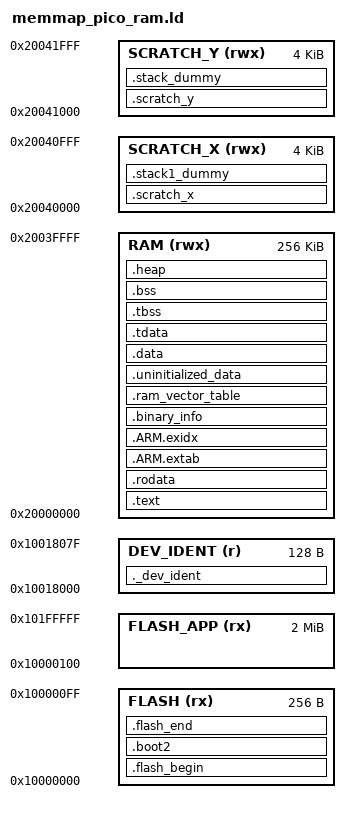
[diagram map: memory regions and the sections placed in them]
/* RAM-only linker script for RP2040 Pico Frankly Bootloader
   Boot2 stage is in flash (required), entire bootloader runs from RAM
   This eliminates all XIP conflicts during flash operations
*/

MEMORY
{
    /* Boot2 stage MUST be in flash - this is hardcoded in RP2040 ROM */
    FLASH(rx) : ORIGIN = 0x10000000, LENGTH = 256
    /* Reserve rest of flash for applications */
    FLASH_APP(rx) : ORIGIN = 0x10000100, LENGTH = 2048k - 256
    /* Entire bootloader runs from RAM */
    RAM(rwx) : ORIGIN = 0x20000000, LENGTH = 256k
    SCRATCH_X(rwx) : ORIGIN = 0x20040000, LENGTH = 4k
    SCRATCH_Y(rwx) : ORIGIN = 0x20041000, LENGTH = 4k
    /* Device identification section in flash for bootflash tool */
    DEV_IDENT(r) : ORIGIN = 0x10018000, LENGTH = 128
}

ENTRY(_entry_point)

SECTIONS
{
    .flash_begin : {
        __flash_binary_start = .;
    } > FLASH

    /* Boot2 stage MUST be in flash - RP2040 ROM requirement */
    .boot2 : {
        __boot2_start__ = .;
        KEEP (*(.boot2))
        __boot2_end__ = .;
    } > FLASH

    .flash_end : {
        PROVIDE(__flash_binary_end = .);
    } > FLASH

    ASSERT(__boot2_end__ - __boot2_start__ == 256,
        "ERROR: Pico second stage bootloader must be 256 bytes in size")

    /* Device identification section for bootflash tool */
    ._dev_ident :
    {
        . = ALIGN(4);
        KEEP(*(._dev_ident))
        . = ALIGN(4);
    } > DEV_IDENT

    /* Everything else runs from RAM - eliminates XIP conflicts */
    .text : {
        __logical_binary_start = .;
        __ram_start__ = .;

        /* Vector table and reset code */
        KEEP (*(.vectors))
        KEEP (*(.binary_info_header))
        __binary_info_header_end = .;
        KEEP (*(.embedded_block))
        __embedded_block_end = .;
        KEEP (*(.reset))

        /* All code in RAM */
        *(.init)
        *(.text*)
        *(.fini)

        /* C++ constructors/destructors */
        *crtbegin.o(.ctors)
        *crtbegin?.o(.ctors)
        *(EXCLUDE_FILE(*crtend?.o *crtend.o) .ctors)
        *(SORT(.ctors.*))
        *(.ctors)
        *crtbegin.o(.dtors)
        *crtbegin?.o(.dtors)
        *(EXCLUDE_FILE(*crtend?.o *crtend.o) .dtors)
        *(SORT(.dtors.*))
        *(.dtors)

        . = ALIGN(4);
        /* preinit data */
        PROVIDE_HIDDEN (__preinit_array_start = .);
        KEEP(*(SORT(.preinit_array.*)))
        KEEP(*(.preinit_array))
        PROVIDE_HIDDEN (__preinit_array_end = .);

        . = ALIGN(4);
        /* init data */
        PROVIDE_HIDDEN (__init_array_start = .);
        KEEP(*(SORT(.init_array.*)))
        KEEP(*(.init_array))
        PROVIDE_HIDDEN (__init_array_end = .);

        . = ALIGN(4);
        /* finit data */
        PROVIDE_HIDDEN (__fini_array_start = .);
        *(SORT(.fini_array.*))
        *(.fini_array)
        PROVIDE_HIDDEN (__fini_array_end = .);

        *(.eh_frame*)
        . = ALIGN(4);
    } > RAM

    .rodata : {
        /* All read-only data in RAM */
        *(.rodata*)
        . = ALIGN(4);
        *(SORT_BY_ALIGNMENT(SORT_BY_NAME(.flashdata*)))
        . = ALIGN(4);
    } > RAM

    .ARM.extab :
    {
        *(.ARM.extab* .gnu.linkonce.armextab.*)
    } > RAM

    __exidx_start = .;
    .ARM.exidx :
    {
        *(.ARM.exidx* .gnu.linkonce.armexidx.*)
    } > RAM
    __exidx_end = .;

    /* Machine inspectable binary information */
    . = ALIGN(4);
    __binary_info_start = .;
    .binary_info :
    {
        KEEP(*(.binary_info.keep.*))
        *(.binary_info.*)
    } > RAM
    __binary_info_end = .;
    . = ALIGN(4);

    .ram_vector_table (NOLOAD): {
        *(.ram_vector_table)
    } > RAM

    .uninitialized_data (NOLOAD): {
        . = ALIGN(4);
        *(.uninitialized_data*)
    } > RAM

    .data : {
        __data_start__ = .;
        *(vtable)
        *(.time_critical*)
        *(.data*)
        . = ALIGN(4);
        *(.after_data.*)
        . = ALIGN(4);

        /* mutex array */
        PROVIDE_HIDDEN (__mutex_array_start = .);
        KEEP(*(SORT(.mutex_array.*)))
        KEEP(*(.mutex_array))
        PROVIDE_HIDDEN (__mutex_array_end = .);

        . = ALIGN(4);
        *(.jcr)
        . = ALIGN(4);
    } > RAM

    .tdata : {
        . = ALIGN(4);
        *(.tdata .tdata.* .gnu.linkonce.td.*)
        __tdata_end = .;
    } > RAM
    PROVIDE(__data_end__ = .);

    /* No load address needed since everything is in RAM */
    __etext = .;

    .tbss (NOLOAD) : {
        . = ALIGN(4);
        __bss_start__ = .;
        __tls_base = .;
        *(.tbss .tbss.* .gnu.linkonce.tb.*)
        *(.tcommon)
        __tls_end = .;
    } > RAM

    .bss (NOLOAD) : {
        . = ALIGN(4);
        __tbss_end = .;
        *(SORT_BY_ALIGNMENT(SORT_BY_NAME(.bss*)))
        *(COMMON)
        . = ALIGN(4);
        __bss_end__ = .;
    } > RAM

    .heap (NOLOAD):
    {
        __end__ = .;
        end = __end__;
        KEEP(*(.heap*))
        __ram_end__ = .;
    } > RAM

    /* Set heap limit to leave space for stack */
    __HeapLimit = ORIGIN(RAM) + LENGTH(RAM) - 8192; /* Reserve 8KB for stack */

    /* Scratch sections (unused in RAM-only bootloader) */
    .scratch_x : {
        __scratch_x_start__ = .;
        *(.scratch_x.*)
        . = ALIGN(4);
        __scratch_x_end__ = .;
    } > SCRATCH_X
    __scratch_x_source__ = LOADADDR(.scratch_x);

    .scratch_y : {
        __scratch_y_start__ = .;
        *(.scratch_y.*)
        . = ALIGN(4);
        __scratch_y_end__ = .;
    } > SCRATCH_Y
    __scratch_y_source__ = LOADADDR(.scratch_y);

    /* Stack setup */
    .stack1_dummy (NOLOAD):
    {
        *(.stack1*)
    } > SCRATCH_X
    .stack_dummy (NOLOAD):
    {
        KEEP(*(.stack*))
    } > SCRATCH_Y

    /* Stack symbols */
    __StackLimit = __HeapLimit;
    __StackOneTop = ORIGIN(SCRATCH_X) + LENGTH(SCRATCH_X);
    __StackTop = ORIGIN(SCRATCH_Y) + LENGTH(SCRATCH_Y);
    __StackOneBottom = __StackOneTop - SIZEOF(.stack1_dummy);
    __StackBottom = __StackTop - SIZEOF(.stack_dummy);
    PROVIDE(__stack = __StackTop);

    /* picolibc and LLVM */
    PROVIDE (__heap_start = __end__);
    PROVIDE (__heap_end = __HeapLimit);
    PROVIDE( __tls_align = MAX(ALIGNOF(.tdata), ALIGNOF(.tbss)) );
    PROVIDE( __tls_size_align = (__tls_size + __tls_align - 1) & ~(__tls_align - 1));
    PROVIDE( __arm32_tls_tcb_offset = MAX(8, __tls_align) );

    /* llvm-libc */
    PROVIDE (_end = __end__);
    PROVIDE (__llvm_libc_heap_limit = __HeapLimit);

    /* Validation */
    ASSERT(__StackLimit >= __HeapLimit, "region RAM overflowed")
    ASSERT( __binary_info_header_end - __logical_binary_start <= 256, "Binary info must be in first 256 bytes of the binary")

    /* Ensure bootloader fits in RAM */
    ASSERT(__ram_end__ - __ram_start__ <= LENGTH(RAM) - 8192, "Bootloader too large for RAM")
}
